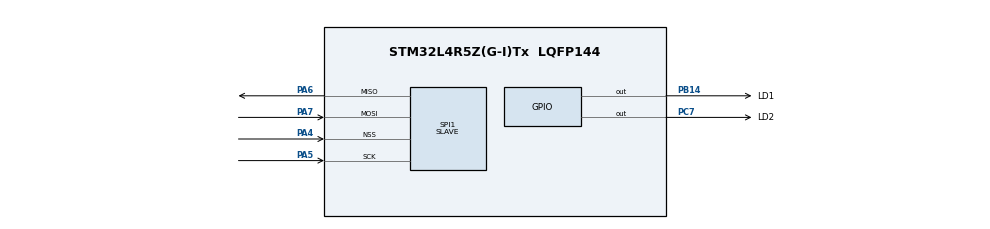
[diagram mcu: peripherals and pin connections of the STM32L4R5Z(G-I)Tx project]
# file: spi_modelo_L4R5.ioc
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Mcu.Family=STM32L4
Mcu.Name=STM32L4R5Z(G-I)Tx
Mcu.Package=LQFP144
NVIC.PriorityGroup=NVIC_PRIORITYGROUP_4
PA4.Mode=NSS_Signal_Hard_Input
PA4.Signal=SPI1_NSS
PA5.Mode=Full_Duplex_Slave
PA5.Signal=SPI1_SCK
PA6.Mode=Full_Duplex_Slave
PA6.Signal=SPI1_MISO
PA7.Mode=Full_Duplex_Slave
PA7.Signal=SPI1_MOSI
PB14.GPIO_Label=LD1
PB14.Signal=GPIO_Output
PC7.GPIO_Label=LD2
PC7.Signal=GPIO_Output
ProjectManager.HeapSize=0x200
ProjectManager.StackSize=0x400
ProjectManager.TargetToolchain=STM32CubeIDE
RCC.HSE_VALUE=8000000
RCC.HSI48_VALUE=48000000
RCC.HSI_VALUE=16000000
RCC.LSE_VALUE=32768
RCC.MSI_VALUE=4000000
RCC.VCOOutputFreq_Value=32000000
SPI1.DataSize=SPI_DATASIZE_8BIT
SPI1.Direction=SPI_DIRECTION_2LINES
SPI1.Mode=SPI_MODE_SLAVE
SPI1.VirtualNSS=VM_NSSHARD
SPI1.VirtualType=VM_SLAVE
board=custom

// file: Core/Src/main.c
/* USER CODE BEGIN Header */
/**
  ******************************************************************************
  * @file           : main.c
  * @brief          : Main program body
  ******************************************************************************
  * @attention
  *
  * Copyright (c) 2025 STMicroelectronics.
  * All rights reserved.
  *
  * This software is licensed under terms that can be found in the LICENSE file
  * in the root directory of this software component.
  * If no LICENSE file comes with this software, it is provided AS-IS.
  *
  ******************************************************************************
  */
/* USER CODE END Header */
#include "main.h"
#include "spi.h"
#include "gpio.h"

/* USER CODE BEGIN PV */
  uint8_t rx_data = 0x00; // Buffer para o sinal recebido do mestre
  uint8_t tx_data = 0xBB; // Resposta que o escravo enviará
/* USER CODE END PV */

void SystemClock_Config(void);

int main(void)
{

  /* MCU Configuration--------------------------------------------------------*/

  /* Reset of all peripherals, Initializes the Flash interface and the Systick. */
  HAL_Init();

  /* Configure the system clock */
  SystemClock_Config();

  /* Initialize all configured peripherals */
  MX_GPIO_Init();
  MX_SPI1_Init();

  /* Infinite loop */
  while (1)
  {

    /* USER CODE BEGIN 3 */

	  // 1. Recebe o sinal do mestre e envia a resposta
	  	      // HAL_SPI_TransmitReceive: função bloqueante
	  	      // O escravo espera o NSS ser ativado pelo mestre para iniciar a comunicação.
	  	      if (HAL_SPI_TransmitReceive(&hspi1, &tx_data, &rx_data, 1, HAL_MAX_DELAY) == HAL_OK) // função bloqueante
	  	      {

	  	        /* if (rx_data != 0xAA) {
	  	        	 HAL_GPIO_TogglePin(LD1_GPIO_Port, LD1_Pin);
	  	        	 HAL_Delay(1000);
	  	         }

	  	         if (rx_data == 0x00) {
	  	        	 HAL_GPIO_TogglePin(LD2_GPIO_Port, LD2_Pin);
	  	        	 HAL_Delay(1000);
	  	         }*/

	  	    }

  }
  /* USER CODE END 3 */
}

void SystemClock_Config(void)
{
  RCC_OscInitTypeDef RCC_OscInitStruct = {0};
  RCC_ClkInitTypeDef RCC_ClkInitStruct = {0};

  /** Configure the main internal regulator output voltage
  */
  if (HAL_PWREx_ControlVoltageScaling(PWR_REGULATOR_VOLTAGE_SCALE1) != HAL_OK)
  {
    Error_Handler();
  }

  /** Initializes the RCC Oscillators according to the specified parameters
  * in the RCC_OscInitTypeDef structure.
  */
  RCC_OscInitStruct.OscillatorType = RCC_OSCILLATORTYPE_MSI;
  RCC_OscInitStruct.MSIState = RCC_MSI_ON;
  RCC_OscInitStruct.MSICalibrationValue = 0;
  RCC_OscInitStruct.MSIClockRange = RCC_MSIRANGE_6;
  RCC_OscInitStruct.PLL.PLLState = RCC_PLL_NONE;
  if (HAL_RCC_OscConfig(&RCC_OscInitStruct) != HAL_OK)
  {
    Error_Handler();
  }

  /** Initializes the CPU, AHB and APB buses clocks
  */
  RCC_ClkInitStruct.ClockType = RCC_CLOCKTYPE_HCLK|RCC_CLOCKTYPE_SYSCLK
                              |RCC_CLOCKTYPE_PCLK1|RCC_CLOCKTYPE_PCLK2;
  RCC_ClkInitStruct.SYSCLKSource = RCC_SYSCLKSOURCE_MSI;
  RCC_ClkInitStruct.AHBCLKDivider = RCC_SYSCLK_DIV1;
  RCC_ClkInitStruct.APB1CLKDivider = RCC_HCLK_DIV1;
  RCC_ClkInitStruct.APB2CLKDivider = RCC_HCLK_DIV1;

  if (HAL_RCC_ClockConfig(&RCC_ClkInitStruct, FLASH_LATENCY_0) != HAL_OK)
  {
    Error_Handler();
  }
}

void Error_Handler(void)
{
  __disable_irq();
  while (1)
  {
  }
}
